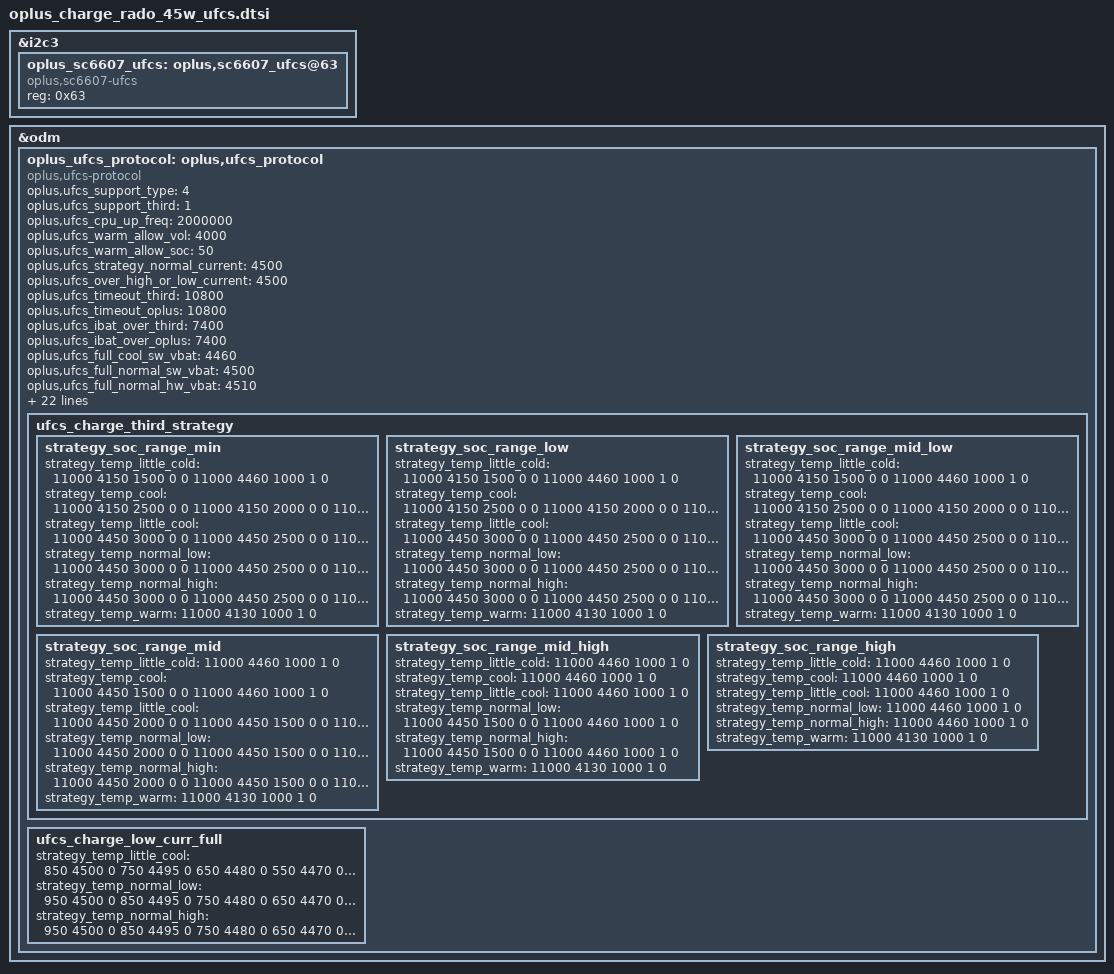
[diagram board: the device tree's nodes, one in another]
&i2c3 {
	oplus_sc6607_ufcs:oplus,sc6607_ufcs@63 {
		status = "okay";
		compatible = "oplus,sc6607-ufcs";
		reg = <0x63>;
	};
};

&odm {
	oplus_ufcs_protocol: oplus,ufcs_protocol {
		status = "ok";
		compatible = "oplus,ufcs-protocol";
	};
};

&oplus_ufcs_protocol {
	oplus,ufcs_support_type = <4>;
	oplus,ufcs_support_third = <1>;
	oplus,ufcs_cpu_up_freq = <2000000>;
	oplus,ufcs_warm_allow_vol = <4000>;
	oplus,ufcs_warm_allow_soc = <50>;
	oplus,ufcs_strategy_normal_current = <4500>;//6A
	oplus,ufcs_over_high_or_low_current = <4500>;
	oplus,ufcs_timeout_third = <10800>;
	oplus,ufcs_timeout_oplus = <10800>;
	oplus,ufcs_ibat_over_third = <7400>;
	oplus,ufcs_ibat_over_oplus = <7400>;
	oplus,ufcs_full_cool_sw_vbat = <4460>;
	oplus,ufcs_full_normal_sw_vbat = <4500>;
	oplus,ufcs_full_normal_hw_vbat = <4510>;
	oplus,ufcs_full_ffc_vbat = <4460>;
	oplus,ufcs_full_warm_vbat = <4130>;
	oplus,ufcs_full_cool_sw_vbat_third = <4460>;
	oplus,ufcs_full_normal_sw_vbat_third= <4460>;
	oplus,ufcs_full_normal_hw_vbat_third = <4470>;
	oplus,ufcs_freq_mincore = <968000>;
	oplus,ufcs_freq_midcore = <1418000>;
	oplus,ufcs_freq_maxcore = <1418000>;
	oplus,ufcs_current_change_timeout = <100>;
	oplus,ufcs_r_default = <270 45 10 45 20 20 20>;
	oplus,ufcs_rmos_mohm = <5>;
	oplus,ufcs_r_limit = <150 80 70 50 30>;
	oplus,ufcs_strategy_batt_high_temp = <400 420 430 390 410 420>;
	oplus,ufcs_strategy_high_current = <3000 2000 2000 3000 3000 3000>;
	oplus,ufcs_charge_strategy_soc = <0 20 35 50 75 85 90>;
	oplus,ufcs_charge_strategy_temp = <0 50 120 160 350 440 530>;
	oplus,ufcs_low_curr_full_strategy_temp = <0 120 350 440>;

	ufcs_charge_third_strategy {
		//0 ~ 20
		strategy_soc_range_min {
			strategy_temp_little_cold =	<11000 4150 1500 0 0
				11000 4460 1000 1 0>;
			strategy_temp_cool =		<11000 4150 2500 0 0
				11000 4150 2000 0 0
				11000 4150 1500 0 0
				11000 4460 1000 1 0>;
			strategy_temp_little_cool =	<11000 4450 3000 0 0
				11000 4450 2500 0 0
				11000 4450 2000 0 0
				11000 4450 1500 0 0
				11000 4460 1000 1 0>;
			strategy_temp_normal_low =	<11000 4450 3000 0 0
				11000 4450 2500 0 0
				11000 4450 2000 0 0
				11000 4450 1500 0 0
				11000 4460 1000 1 0>;
			strategy_temp_normal_high =	<11000 4450 3000 0 0
				11000 4450 2500 0 0
				11000 4450 2000 0 0
				11000 4450 1500 0 0
				11000 4460 1000 1 0>;
			strategy_temp_warm =		<11000 4130 1000 1 0>;
		};
		//21 ~ 35
		strategy_soc_range_low {
			strategy_temp_little_cold =	<11000 4150 1500 0 0
				11000 4460 1000 1 0>;
			strategy_temp_cool =		<11000 4150 2500 0 0
				11000 4150 2000 0 0
				11000 4150 1500 0 0
				11000 4460 1000 1 0>;
			strategy_temp_little_cool =	<11000 4450 3000 0 0
				11000 4450 2500 0 0
				11000 4450 2000 0 0
				11000 4450 1500 0 0
				11000 4460 1000 1 0>;
			strategy_temp_normal_low =	<11000 4450 3000 0 0
				11000 4450 2500 0 0
				11000 4450 2000 0 0
				11000 4450 1500 0 0
				11000 4460 1000 1 0>;
			strategy_temp_normal_high =	<11000 4450 3000 0 0
				11000 4450 2500 0 0
				11000 4450 2000 0 0
				11000 4450 1500 0 0
				11000 4460 1000 1 0>;
			strategy_temp_warm =		<11000 4130 1000 1 0>;
		};
		//35 ~ 50
		strategy_soc_range_mid_low {
			strategy_temp_little_cold =	<11000 4150 1500 0 0
				11000 4460 1000 1 0>;
			strategy_temp_cool =		<11000 4150 2500 0 0
				11000 4150 2000 0 0
				11000 4150 1500 0 0
				11000 4460 1000 1 0>;
			strategy_temp_little_cool =	<11000 4450 3000 0 0
				11000 4450 2500 0 0
				11000 4450 2000 0 0
				11000 4450 1500 0 0
				11000 4460 1000 1 0>;
			strategy_temp_normal_low =	<11000 4450 3000 0 0
				11000 4450 2500 0 0
				11000 4450 2000 0 0
				11000 4450 1500 0 0
				11000 4460 1000 1 0>;
			strategy_temp_normal_high =	<11000 4450 3000 0 0
				11000 4450 2500 0 0
				11000 4450 2000 0 0
				11000 4450 1500 0 0
				11000 4460 1000 1 0>;
			strategy_temp_warm =		<11000 4130 1000 1 0>;
		};
		//51 ~ 75
		strategy_soc_range_mid {
			strategy_temp_little_cold =	<11000 4460 1000 1 0>;
			strategy_temp_cool =		<11000 4450 1500 0 0
				11000 4460 1000 1 0>;
			strategy_temp_little_cool =	<11000 4450 2000 0 0
				11000 4450 1500 0 0
				11000 4460 1000 1 0>;
			strategy_temp_normal_low =	<11000 4450 2000 0 0
				11000 4450 1500 0 0
				11000 4460 1000 1 0>;
			strategy_temp_normal_high =	<11000 4450 2000 0 0
				11000 4450 1500 0 0
				11000 4460 1000 1 0>;
			strategy_temp_warm =		<11000 4130 1000 1 0>;
		};
		//76 ~ 85
		strategy_soc_range_mid_high {
			strategy_temp_little_cold =	<11000 4460 1000 1 0>;
			strategy_temp_cool =		<11000 4460 1000 1 0>;
			strategy_temp_little_cool =	<11000 4460 1000 1 0>;
			strategy_temp_normal_low =	<11000 4450 1500 0 0
				11000 4460 1000 1 0>;
			strategy_temp_normal_high =	<11000 4450 1500 0 0
				11000 4460 1000 1 0>;
			strategy_temp_warm =		<11000 4130 1000 1 0>;
		};
		//86 ~ 90
		strategy_soc_range_high {
			strategy_temp_little_cold =	<11000 4460 1000 1 0>;
			strategy_temp_cool =		<11000 4460 1000 1 0>;
			strategy_temp_little_cool =	<11000 4460 1000 1 0>;
			strategy_temp_normal_low =	<11000 4460 1000 1 0>;
			strategy_temp_normal_high =	<11000 4460 1000 1 0>;
			strategy_temp_warm =		<11000 4130 1000 1 0>;
		};
	};

	ufcs_charge_low_curr_full {
		strategy_temp_little_cool = 	<850 4500 0
						 750 4495 0
						 650 4480 0
						 550 4470 0
						 450 4460 1>;
		strategy_temp_normal_low =	<950 4500 0
						 850 4495 0
						 750 4480 0
						 650 4470 0
						 550 4460 1>;
		strategy_temp_normal_high = 	<950 4500 0
						 850 4495 0
						 750 4480 0
						 650 4470 0
						 550 4460 1>;
	};
};

